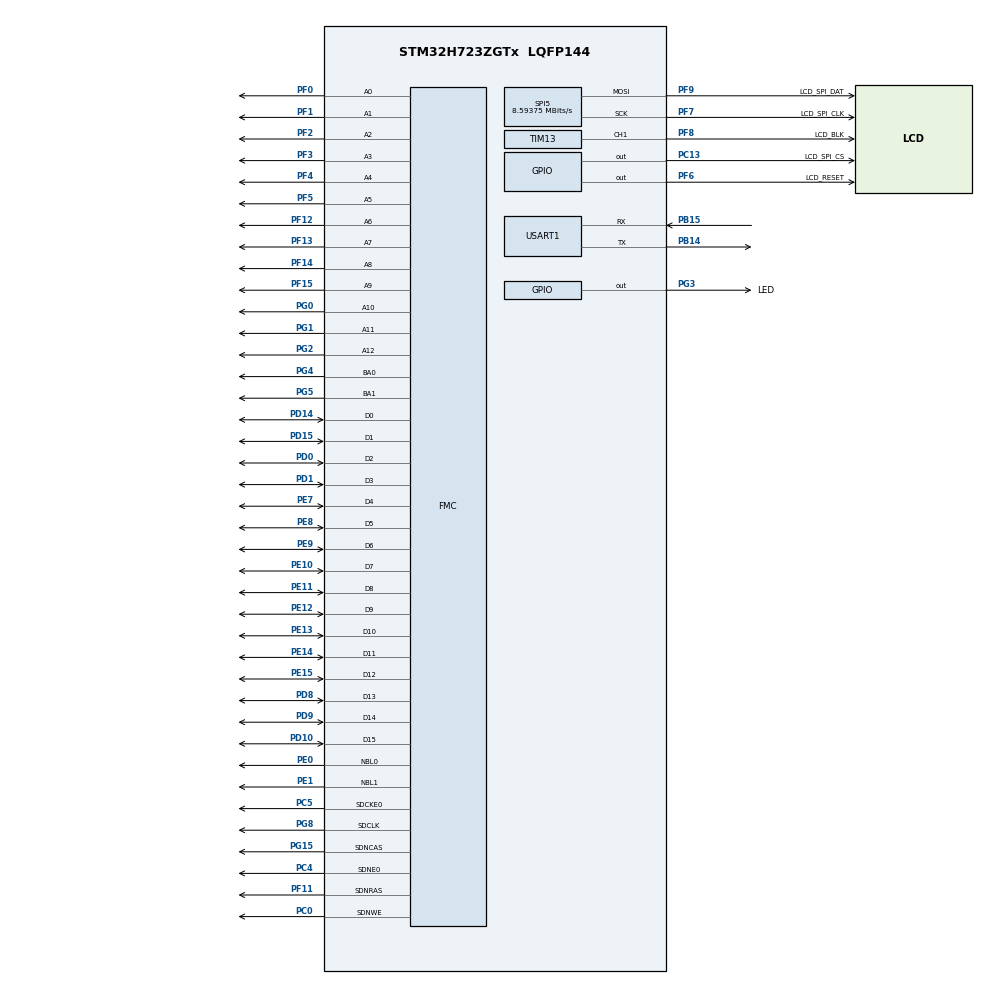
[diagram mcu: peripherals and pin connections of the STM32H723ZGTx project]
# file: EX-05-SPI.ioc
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FMC.CASLatency1=FMC_SDRAM_CAS_LATENCY_2
FMC.ColumnBitsNumber1=FMC_SDRAM_COLUMN_BITS_NUM_9
FMC.ExitSelfRefreshDelay1=7
FMC.LoadToActiveDelay1=2
FMC.RCDDelay1=2
FMC.RPDelay1=2
FMC.ReadBurst1=FMC_SDRAM_RBURST_ENABLE
FMC.RowCycleDelay1=6
FMC.SDClockPeriod1=FMC_SDRAM_CLOCK_PERIOD_3
FMC.SelfRefreshTime1=4
FMC.WriteRecoveryTime1=2
Mcu.Family=STM32H7
Mcu.Name=STM32H723ZGTx
Mcu.Package=LQFP144
NVIC.PriorityGroup=NVIC_PRIORITYGROUP_4
PA13(JTMS/SWDIO).Mode=Serial_Wire
PA13(JTMS/SWDIO).Signal=DEBUG_JTMS-SWDIO
PA14(JTCK/SWCLK).Mode=Serial_Wire
PA14(JTCK/SWCLK).Signal=DEBUG_JTCK-SWCLK
PB14.Mode=Asynchronous
PB14.Signal=USART1_TX
PB15.Mode=Asynchronous
PB15.Signal=USART1_RX
PC0.Signal=FMC_SDNWE
PC13.GPIO_Label=LCD_SPI_CS
PC13.PinState=GPIO_PIN_SET
PC13.Signal=GPIO_Output
PC4.Mode=SdramChipSelect1_1
PC4.Signal=FMC_SDNE0
PC5.Mode=SdramChipSelect1_1
PC5.Signal=FMC_SDCKE0
PD0.Signal=FMC_D2_DA2
PD1.Signal=FMC_D3_DA3
PD10.Signal=FMC_D15_DA15
PD14.Signal=FMC_D0_DA0
PD15.Signal=FMC_D1_DA1
PD8.Signal=FMC_D13_DA13
PD9.Signal=FMC_D14_DA14
PE0.Signal=FMC_NBL0
PE1.Signal=FMC_NBL1
PE10.Signal=FMC_D7_DA7
PE11.Signal=FMC_D8_DA8
PE12.Signal=FMC_D9_DA9
PE13.Signal=FMC_D10_DA10
PE14.Signal=FMC_D11_DA11
PE15.Signal=FMC_D12_DA12
PE7.Signal=FMC_D4_DA4
PE8.Signal=FMC_D5_DA5
PE9.Signal=FMC_D6_DA6
PF0.Signal=FMC_A0
PF1.Signal=FMC_A1
PF11.Signal=FMC_SDNRAS
PF12.Signal=FMC_A6
PF13.Signal=FMC_A7
PF14.Signal=FMC_A8
PF15.Signal=FMC_A9
PF2.Signal=FMC_A2
PF3.Signal=FMC_A3
PF4.Signal=FMC_A4
PF5.Signal=FMC_A5
PF6.GPIO_Label=LCD_RESET
PF6.PinState=GPIO_PIN_SET
PF6.Signal=GPIO_Output
PF7.GPIO_Label=LCD_SPI_CLK
PF7.GPIO_Speed=GPIO_SPEED_FREQ_HIGH
PF7.Mode=TX_Only_Simplex_Unidirect_Master
PF7.Signal=SPI5_SCK
PF8.GPIO_Label=LCD_BLK
PF8.Signal=S_TIM13_CH1
PF9.GPIO_Label=LCD_SPI_DAT
PF9.GPIO_Speed=GPIO_SPEED_FREQ_HIGH
PF9.Mode=TX_Only_Simplex_Unidirect_Master
PF9.Signal=SPI5_MOSI
PG0.Signal=FMC_A10
PG1.Signal=FMC_A11
PG15.Signal=FMC_SDNCAS
PG2.Signal=FMC_A12
PG3.GPIO_Label=LED
PG3.PinState=GPIO_PIN_SET
PG3.Signal=GPIO_Output
PG4.Signal=FMC_A14_BA0
PG5.Signal=FMC_A15_BA1
PG8.Signal=FMC_SDCLK
PH0-OSC_IN.Mode=HSE-External-Oscillator
PH0-OSC_IN.Signal=RCC_OSC_IN
PH1-OSC_OUT.Mode=HSE-External-Oscillator
PH1-OSC_OUT.Signal=RCC_OSC_OUT
ProjectManager.HeapSize=0x200
ProjectManager.StackSize=0x400
ProjectManager.TargetToolchain=STM32CubeIDE
RCC.ADCFreq_Value=50390625
RCC.APB1Freq_Value=137500000
RCC.APB2Freq_Value=137500000
RCC.APB3Freq_Value=137500000
RCC.APB4Freq_Value=137500000
RCC.CortexFreq_Value=550000000
RCC.D1PPRE=RCC_APB3_DIV2
RCC.D2PPRE1=RCC_APB1_DIV2
RCC.D2PPRE2=RCC_APB2_DIV2
RCC.D3PPRE=RCC_APB4_DIV2
RCC.DIVM1=2
RCC.DIVN1=44
RCC.DIVP1=1
RCC.HCLKFreq_Value=275000000
RCC.HPRE=RCC_HCLK_DIV2
RCC.PLLFRACN=0
RCC.PLLSourceVirtual=RCC_PLLSOURCE_HSE
RCC.SYSCLKFreq_VALUE=550000000
RCC.SYSCLKSource=RCC_SYSCLKSOURCE_PLLCLK
RCC.USBFreq_Value=275000000
SH.FMC_A0.0=FMC_A0,13b-sda1
SH.FMC_A1.0=FMC_A1,13b-sda1
SH.FMC_A10.0=FMC_A10,13b-sda1
SH.FMC_A11.0=FMC_A11,13b-sda1
SH.FMC_A12.0=FMC_A12,13b-sda1
SH.FMC_A14_BA0.0=FMC_BA0,FourSdramBanks1
SH.FMC_A15_BA1.0=FMC_BA1,FourSdramBanks1
SH.FMC_A2.0=FMC_A2,13b-sda1
SH.FMC_A3.0=FMC_A3,13b-sda1
SH.FMC_A4.0=FMC_A4,13b-sda1
SH.FMC_A5.0=FMC_A5,13b-sda1
SH.FMC_A6.0=FMC_A6,13b-sda1
SH.FMC_A7.0=FMC_A7,13b-sda1
SH.FMC_A8.0=FMC_A8,13b-sda1
SH.FMC_A9.0=FMC_A9,13b-sda1
SH.FMC_D0_DA0.0=FMC_D0,sd-16b-d1
SH.FMC_D10_DA10.0=FMC_D10,sd-16b-d1
SH.FMC_D11_DA11.0=FMC_D11,sd-16b-d1
SH.FMC_D12_DA12.0=FMC_D12,sd-16b-d1
SH.FMC_D13_DA13.0=FMC_D13,sd-16b-d1
SH.FMC_D14_DA14.0=FMC_D14,sd-16b-d1
SH.FMC_D15_DA15.0=FMC_D15,sd-16b-d1
SH.FMC_D1_DA1.0=FMC_D1,sd-16b-d1
SH.FMC_D2_DA2.0=FMC_D2,sd-16b-d1
SH.FMC_D3_DA3.0=FMC_D3,sd-16b-d1
SH.FMC_D4_DA4.0=FMC_D4,sd-16b-d1
SH.FMC_D5_DA5.0=FMC_D5,sd-16b-d1
SH.FMC_D6_DA6.0=FMC_D6,sd-16b-d1
SH.FMC_D7_DA7.0=FMC_D7,sd-16b-d1
SH.FMC_D8_DA8.0=FMC_D8,sd-16b-d1
SH.FMC_D9_DA9.0=FMC_D9,sd-16b-d1
SH.FMC_NBL0.0=FMC_NBL0,Sd2ByteEnable1
SH.FMC_NBL1.0=FMC_NBL1,Sd2ByteEnable1
SH.FMC_SDCLK.0=FMC_SDCLK,13b-sda1
SH.FMC_SDNCAS.0=FMC_SDNCAS,13b-sda1
SH.FMC_SDNRAS.0=FMC_SDNRAS,13b-sda1
SH.FMC_SDNWE.0=FMC_SDNWE,13b-sda1
SH.S_TIM13_CH1.0=TIM13_CH1,PWM Generation1 CH1
SPI5.BaudRatePrescaler=SPI_BAUDRATEPRESCALER_16
SPI5.CalculateBaudRate=8.59375 MBits/s
SPI5.DataSize=SPI_DATASIZE_9BIT
SPI5.Direction=SPI_DIRECTION_2LINES_TXONLY
SPI5.Mode=SPI_MODE_MASTER
SPI5.VirtualType=VM_MASTER
TIM13.Channel=TIM_CHANNEL_1
TIM13.Period=255
TIM13.Prescaler=53
USART1.VirtualMode-Asynchronous=VM_ASYNC
VP_TIM13_VS_ClockSourceINT.Mode=Enable_Timer
board=custom

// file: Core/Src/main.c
/* USER CODE BEGIN Header */
/**
  ******************************************************************************
  * @file           : main.c
  * @brief          : Main program body
  ******************************************************************************
  * @attention
  *
  * Copyright (c) 2024 STMicroelectronics.
  * All rights reserved.
  *
  * This software is licensed under terms that can be found in the LICENSE file
  * in the root directory of this software component.
  * If no LICENSE file comes with this software, it is provided AS-IS.
  *
  ******************************************************************************
  */
/* USER CODE END Header */
#include "main.h"
#include "spi.h"
#include "tim.h"
#include "usart.h"
#include "gpio.h"
#include "fmc.h"

/* USER CODE BEGIN Includes */

#include "sdram.h"
#include "st7701.h"

/* USER CODE END Includes */

void SystemClock_Config(void);

int main(void)
{

  /* MCU Configuration--------------------------------------------------------*/

  /* Reset of all peripherals, Initializes the Flash interface and the Systick. */
  HAL_Init();

  /* Configure the system clock */
  SystemClock_Config();

  /* Initialize all configured peripherals */
  MX_GPIO_Init();
  MX_USART1_UART_Init();
  MX_FMC_Init();
  MX_TIM13_Init();
  MX_SPI5_Init();
  /* USER CODE BEGIN 2 */

  sdramInit();
  st7701Init();

  HAL_TIM_PWM_Start(&htim13, TIM_CHANNEL_1);
  htim13.Instance->CCR1 = 255;

  /* USER CODE END 2 */

  /* Infinite loop */
  /* USER CODE BEGIN WHILE */
  while (1)
  {
    HAL_GPIO_TogglePin(LED_GPIO_Port, LED_Pin);
    HAL_Delay(500);

    /* USER CODE END WHILE */

  }
}

void SystemClock_Config(void)
{
  RCC_OscInitTypeDef RCC_OscInitStruct = {0};
  RCC_ClkInitTypeDef RCC_ClkInitStruct = {0};

  /** Supply configuration update enable
  */
  HAL_PWREx_ConfigSupply(PWR_LDO_SUPPLY);

  /** Configure the main internal regulator output voltage
  */
  __HAL_PWR_VOLTAGESCALING_CONFIG(PWR_REGULATOR_VOLTAGE_SCALE0);

  while(!__HAL_PWR_GET_FLAG(PWR_FLAG_VOSRDY)) {}

  /** Initializes the RCC Oscillators according to the specified parameters
  * in the RCC_OscInitTypeDef structure.
  */
  RCC_OscInitStruct.OscillatorType = RCC_OSCILLATORTYPE_HSE;
  RCC_OscInitStruct.HSEState = RCC_HSE_ON;
  RCC_OscInitStruct.PLL.PLLState = RCC_PLL_ON;
  RCC_OscInitStruct.PLL.PLLSource = RCC_PLLSOURCE_HSE;
  RCC_OscInitStruct.PLL.PLLM = 2;
  RCC_OscInitStruct.PLL.PLLN = 44;
  RCC_OscInitStruct.PLL.PLLP = 1;
  RCC_OscInitStruct.PLL.PLLQ = 2;
  RCC_OscInitStruct.PLL.PLLR = 2;
  RCC_OscInitStruct.PLL.PLLRGE = RCC_PLL1VCIRANGE_3;
  RCC_OscInitStruct.PLL.PLLVCOSEL = RCC_PLL1VCOWIDE;
  RCC_OscInitStruct.PLL.PLLFRACN = 0;
  if (HAL_RCC_OscConfig(&RCC_OscInitStruct) != HAL_OK)
  {
    Error_Handler();
  }

  /** Initializes the CPU, AHB and APB buses clocks
  */
  RCC_ClkInitStruct.ClockType = RCC_CLOCKTYPE_HCLK|RCC_CLOCKTYPE_SYSCLK
                              |RCC_CLOCKTYPE_PCLK1|RCC_CLOCKTYPE_PCLK2
                              |RCC_CLOCKTYPE_D3PCLK1|RCC_CLOCKTYPE_D1PCLK1;
  RCC_ClkInitStruct.SYSCLKSource = RCC_SYSCLKSOURCE_PLLCLK;
  RCC_ClkInitStruct.SYSCLKDivider = RCC_SYSCLK_DIV1;
  RCC_ClkInitStruct.AHBCLKDivider = RCC_HCLK_DIV2;
  RCC_ClkInitStruct.APB3CLKDivider = RCC_APB3_DIV2;
  RCC_ClkInitStruct.APB1CLKDivider = RCC_APB1_DIV2;
  RCC_ClkInitStruct.APB2CLKDivider = RCC_APB2_DIV2;
  RCC_ClkInitStruct.APB4CLKDivider = RCC_APB4_DIV2;

  if (HAL_RCC_ClockConfig(&RCC_ClkInitStruct, FLASH_LATENCY_3) != HAL_OK)
  {
    Error_Handler();
  }
}

void Error_Handler(void)
{
  __disable_irq();
  while (1)
  {
  }
}
